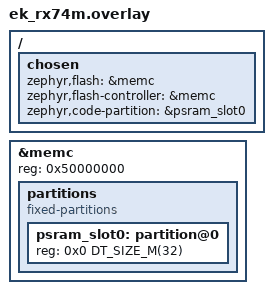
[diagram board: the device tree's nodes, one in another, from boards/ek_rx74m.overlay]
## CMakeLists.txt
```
# SPDX-License-Identifier: Apache-2.0

cmake_minimum_required(VERSION 3.20.0)

find_package(Zephyr REQUIRED HINTS $ENV{ZEPHYR_BASE})
project(ospi_ram_build)

FILE(GLOB app_sources src/*.c)
target_sources(app PRIVATE ${app_sources})
```

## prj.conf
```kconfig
CONFIG_PRINTK=y
CONFIG_GPIO=y
```

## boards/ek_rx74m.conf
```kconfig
CONFIG_BOOTLOADER_MCUBOOT=y
CONFIG_SOC_RX74M_SKIP_OSPI_CLOCK_SETUP=y
```

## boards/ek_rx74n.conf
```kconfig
CONFIG_BOOTLOADER_MCUBOOT=y
CONFIG_SOC_RX74N_SKIP_OSPI_CLOCK_SETUP=y
```

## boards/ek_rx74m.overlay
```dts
/delete-node/ &psram;

/ {
	chosen {
		zephyr,flash = &memc;
		zephyr,flash-controller = &memc;
		zephyr,code-partition = &psram_slot0;
	};
};

&memc {
	reg = <0x50000000>;
	ranges;
	partitions {
		compatible = "fixed-partitions";
		#address-cells = <1>;
		#size-cells = <1>;

		psram_slot0: partition@0 {
			reg = <0x0 DT_SIZE_M(32)>;
		};
	};
};
```

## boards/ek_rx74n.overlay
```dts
/delete-node/ &psram;

/ {
	chosen {
		zephyr,flash = &memc;
		zephyr,flash-controller = &memc;
		zephyr,code-partition = &psram_slot0;
	};
};

&memc {
	reg = <0x10000000 DT_SIZE_M(32)>;
	cs = <0>;
	partitions {
		compatible = "fixed-partitions";
		#address-cells = <1>;
		#size-cells = <1>;

		psram_slot0: partition@0 {
			reg = <0x0 DT_SIZE_M(32)>;
		};
	};
};
```

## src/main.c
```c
/*
 * Copyright (c) 2026 Renesas Electronics Corporation
 *
 * SPDX-License-Identifier: Apache-2.0
 */

#include <zephyr/kernel.h>
#include <zephyr/sys/reboot.h>

extern void _start();
extern uint8_t __exvectors_start[];
extern uint8_t rvectors_start[];

/* Main entry point */
int main(void)
{
	printk("Launching primary slot application on %s\n", CONFIG_BOARD);
	printk("Address of Kernel _start function %p\n", (void *)_start);
	printk("Address of main %p\n", (int *)main);
	printk("Address of EXVECTORS section: start %p\n", (uint8_t *)__exvectors_start);
	printk("Address of relocatable vector table section: start %p\n", (uint8_t *)rvectors_start);

	return 0;
}
```
